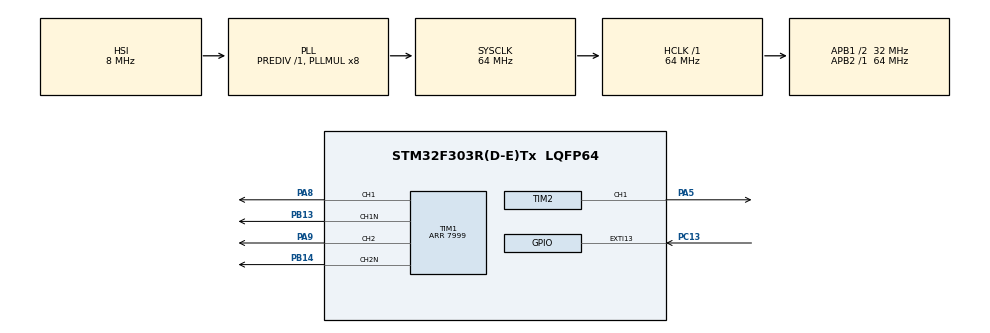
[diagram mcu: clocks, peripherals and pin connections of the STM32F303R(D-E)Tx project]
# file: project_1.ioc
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Dma.Request0=TIM1_CH1
Dma.TIM1_CH1.0.Direction=DMA_MEMORY_TO_PERIPH
Dma.TIM1_CH1.0.Instance=DMA1_Channel2
Dma.TIM1_CH1.0.MemDataAlignment=DMA_MDATAALIGN_HALFWORD
Dma.TIM1_CH1.0.MemInc=DMA_MINC_DISABLE
Dma.TIM1_CH1.0.Mode=DMA_CIRCULAR
Dma.TIM1_CH1.0.PeriphDataAlignment=DMA_PDATAALIGN_HALFWORD
Dma.TIM1_CH1.0.PeriphInc=DMA_PINC_DISABLE
Dma.TIM1_CH1.0.Priority=DMA_PRIORITY_VERY_HIGH
Mcu.Family=STM32F3
Mcu.Name=STM32F303R(D-E)Tx
Mcu.Package=LQFP64
NVIC.DMA1_Channel2_IRQn=true\:0\:0\:false\:false\:true\:false\:true
NVIC.EXTI15_10_IRQn=true\:5\:0\:true\:false\:true\:true\:true
NVIC.PriorityGroup=NVIC_PRIORITYGROUP_4
NVIC.TIM1_UP_TIM16_IRQn=true\:4\:0\:true\:false\:true\:true\:true
NVIC.TIM3_IRQn=true\:6\:0\:true\:false\:true\:true\:true
PA13.Mode=Serial_Wire
PA13.Signal=SYS_JTMS-SWDIO
PA14.Mode=Serial_Wire
PA14.Signal=SYS_JTCK-SWCLK
PA5.Signal=S_TIM2_CH1_ETR
PA8.Signal=S_TIM1_CH1
PA9.Signal=S_TIM1_CH2
PB13.Mode=PWM Generation1 CH1 CH1N
PB13.Signal=TIM1_CH1N
PB14.Mode=PWM Generation2 CH2 CH2N
PB14.Signal=TIM1_CH2N
PC13.Signal=GPXTI13
ProjectManager.HeapSize=0x200
ProjectManager.StackSize=0x400
ProjectManager.TargetToolchain=STM32CubeIDE
RCC.AHBFreq_Value=64000000
RCC.APB1CLKDivider=RCC_HCLK_DIV2
RCC.APB1Freq_Value=32000000
RCC.APB1TimFreq_Value=64000000
RCC.APB2Freq_Value=64000000
RCC.APB2TimFreq_Value=64000000
RCC.CortexFreq_Value=64000000
RCC.HCLKFreq_Value=64000000
RCC.HSE_VALUE=8000000
RCC.HSI_VALUE=8000000
RCC.LSE_VALUE=32768
RCC.PLLMUL=RCC_PLL_MUL8
RCC.SYSCLKFreq_VALUE=64000000
RCC.SYSCLKSourceVirtual=RCC_SYSCLKSOURCE_PLLCLK
RCC.USBFreq_Value=64000000
SH.S_TIM1_CH1.0=TIM1_CH1,PWM Generation1 CH1 CH1N
SH.S_TIM1_CH2.0=TIM1_CH2,PWM Generation2 CH2 CH2N
SH.S_TIM2_CH1_ETR.0=TIM2_CH1,PWM Generation1 CH1
TIM1.Channel-PWM\ Generation1\ CH1\ CH1N=TIM_CHANNEL_1
TIM1.Channel-PWM\ Generation2\ CH2\ CH2N=TIM_CHANNEL_2
TIM1.CounterMode=TIM_COUNTERMODE_CENTERALIGNED1
TIM1.DeadTime=77
TIM1.Period=7999
TIM1.Pulse-PWM\ Generation1\ CH1\ CH1N=0
TIM1.Pulse-PWM\ Generation2\ CH2\ CH2N=0
TIM2.Channel-PWM\ Generation1\ CH1=TIM_CHANNEL_1
TIM2.Period=249
TIM2.Prescaler=63999
TIM2.Pulse-PWM\ Generation1\ CH1=124
TIM3.Period=249
TIM3.Prescaler=63999
VP_TIM1_VS_ClockSourceINT.Mode=Internal
VP_TIM2_VS_ClockSourceINT.Mode=Internal
VP_TIM3_VS_ClockSourceINT.Mode=Internal
VP_TIM3_VS_OPM.Mode=OPM_bit
board=custom

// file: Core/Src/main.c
/* USER CODE BEGIN Header */
/**
  ******************************************************************************
  * @file           : main.c
  * @brief          : Main program body
  ******************************************************************************
  * @attention
  *
  * <h2><center>&copy; Copyright (c) 2021 STMicroelectronics.
  * All rights reserved.</center></h2>
  *
  * This software component is licensed by ST under BSD 3-Clause license,
  * the "License"; You may not use this file except in compliance with the
  * License. You may obtain a copy of the License at:
  *                        opensource.org/licenses/BSD-3-Clause
  *
  ******************************************************************************
  */
/* USER CODE END Header */

#include "main.h"

/* USER CODE BEGIN Includes */
#include "prj.h"
/* USER CODE END Includes */

TIM_HandleTypeDef htim2;
TIM_HandleTypeDef htim3;

void SystemClock_Config(void);
static void MX_GPIO_Init(void);
static void MX_DMA_Init(void);
static void MX_TIM1_Init(void);
static void MX_TIM3_Init(void);
static void MX_TIM2_Init(void);

/* USER CODE BEGIN 0 */
extern int16_t ccr1;
/* USER CODE END 0 */

int main(void)
{

  /* MCU Configuration--------------------------------------------------------*/

  /* Reset of all peripherals, Initializes the Flash interface and the Systick. */
  HAL_Init();

  /* USER CODE BEGIN Init */
  machine_state	= STATE_CNT;

  /* USER CODE END Init */

  /* Configure the system clock */
  SystemClock_Config();

  /* Initialize all configured peripherals */
  MX_GPIO_Init();
  MX_DMA_Init();
  MX_TIM1_Init();
  MX_TIM3_Init();
  MX_TIM2_Init();
  /* USER CODE BEGIN 2 */
  LL_TIM_ClearFlag_UPDATE(TIM3);
  LL_TIM_EnableIT_UPDATE(TIM3);

  LL_TIM_EnableDMAReq_CC1(TIM1);
  LL_DMA_SetPeriphAddress(DMA1, LL_DMA_CHANNEL_2, (uint32_t)&TIM1->CCR1);
  LL_DMA_SetMemoryAddress(DMA1, LL_DMA_CHANNEL_2, (uint32_t)&ccr1);
  LL_DMA_SetDataLength(DMA1, LL_DMA_CHANNEL_2, 1);
  LL_DMA_EnableChannel(DMA1, LL_DMA_CHANNEL_2);
  /* USER CODE END 2 */

  /* Infinite loop */
  /* USER CODE BEGIN WHILE */
  while (1)
  {
    state_machine_executor();
    /* USER CODE END WHILE */

  }
}

void SystemClock_Config(void)
{
  RCC_OscInitTypeDef RCC_OscInitStruct = {0};
  RCC_ClkInitTypeDef RCC_ClkInitStruct = {0};
  RCC_PeriphCLKInitTypeDef PeriphClkInit = {0};

  /** Initializes the CPU, AHB and APB busses clocks
  */
  RCC_OscInitStruct.OscillatorType = RCC_OSCILLATORTYPE_HSI;
  RCC_OscInitStruct.HSIState = RCC_HSI_ON;
  RCC_OscInitStruct.HSICalibrationValue = RCC_HSICALIBRATION_DEFAULT;
  RCC_OscInitStruct.PLL.PLLState = RCC_PLL_ON;
  RCC_OscInitStruct.PLL.PLLSource = RCC_PLLSOURCE_HSI;
  RCC_OscInitStruct.PLL.PLLMUL = RCC_PLL_MUL8;
  RCC_OscInitStruct.PLL.PREDIV = RCC_PREDIV_DIV1;
  if (HAL_RCC_OscConfig(&RCC_OscInitStruct) != HAL_OK)
  {
    Error_Handler();
  }
  /** Initializes the CPU, AHB and APB busses clocks
  */
  RCC_ClkInitStruct.ClockType = RCC_CLOCKTYPE_HCLK|RCC_CLOCKTYPE_SYSCLK
                              |RCC_CLOCKTYPE_PCLK1|RCC_CLOCKTYPE_PCLK2;
  RCC_ClkInitStruct.SYSCLKSource = RCC_SYSCLKSOURCE_PLLCLK;
  RCC_ClkInitStruct.AHBCLKDivider = RCC_SYSCLK_DIV1;
  RCC_ClkInitStruct.APB1CLKDivider = RCC_HCLK_DIV2;
  RCC_ClkInitStruct.APB2CLKDivider = RCC_HCLK_DIV1;

  if (HAL_RCC_ClockConfig(&RCC_ClkInitStruct, FLASH_LATENCY_2) != HAL_OK)
  {
    Error_Handler();
  }
  PeriphClkInit.PeriphClockSelection = RCC_PERIPHCLK_TIM1|RCC_PERIPHCLK_TIM2
                              |RCC_PERIPHCLK_TIM34;
  PeriphClkInit.Tim1ClockSelection = RCC_TIM1CLK_HCLK;
  PeriphClkInit.Tim2ClockSelection = RCC_TIM2CLK_HCLK;
  PeriphClkInit.Tim34ClockSelection = RCC_TIM34CLK_HCLK;
  if (HAL_RCCEx_PeriphCLKConfig(&PeriphClkInit) != HAL_OK)
  {
    Error_Handler();
  }
}

static void MX_TIM1_Init(void)
{

  LL_TIM_InitTypeDef TIM_InitStruct = {0};
  LL_TIM_OC_InitTypeDef TIM_OC_InitStruct = {0};
  LL_TIM_BDTR_InitTypeDef TIM_BDTRInitStruct = {0};

  LL_GPIO_InitTypeDef GPIO_InitStruct = {0};

  /* Peripheral clock enable */
  LL_APB2_GRP1_EnableClock(LL_APB2_GRP1_PERIPH_TIM1);

  /* TIM1 DMA Init */

  /* TIM1_CH1 Init */
  LL_DMA_SetDataTransferDirection(DMA1, LL_DMA_CHANNEL_2, LL_DMA_DIRECTION_MEMORY_TO_PERIPH);

  LL_DMA_SetChannelPriorityLevel(DMA1, LL_DMA_CHANNEL_2, LL_DMA_PRIORITY_VERYHIGH);

  LL_DMA_SetMode(DMA1, LL_DMA_CHANNEL_2, LL_DMA_MODE_CIRCULAR);

  LL_DMA_SetPeriphIncMode(DMA1, LL_DMA_CHANNEL_2, LL_DMA_PERIPH_NOINCREMENT);

  LL_DMA_SetMemoryIncMode(DMA1, LL_DMA_CHANNEL_2, LL_DMA_MEMORY_NOINCREMENT);

  LL_DMA_SetPeriphSize(DMA1, LL_DMA_CHANNEL_2, LL_DMA_PDATAALIGN_HALFWORD);

  LL_DMA_SetMemorySize(DMA1, LL_DMA_CHANNEL_2, LL_DMA_MDATAALIGN_HALFWORD);

  /* TIM1 interrupt Init */
  NVIC_SetPriority(TIM1_UP_TIM16_IRQn, NVIC_EncodePriority(NVIC_GetPriorityGrouping(),4, 0));
  NVIC_EnableIRQ(TIM1_UP_TIM16_IRQn);

  TIM_InitStruct.Prescaler = 0;
  TIM_InitStruct.CounterMode = LL_TIM_COUNTERMODE_CENTER_UP;
  TIM_InitStruct.Autoreload = 7999;
  TIM_InitStruct.ClockDivision = LL_TIM_CLOCKDIVISION_DIV1;
  TIM_InitStruct.RepetitionCounter = 0;
  LL_TIM_Init(TIM1, &TIM_InitStruct);
  LL_TIM_DisableARRPreload(TIM1);
  LL_TIM_SetClockSource(TIM1, LL_TIM_CLOCKSOURCE_INTERNAL);
  LL_TIM_OC_EnablePreload(TIM1, LL_TIM_CHANNEL_CH1);
  TIM_OC_InitStruct.OCMode = LL_TIM_OCMODE_PWM1;
  TIM_OC_InitStruct.OCState = LL_TIM_OCSTATE_DISABLE;
  TIM_OC_InitStruct.OCNState = LL_TIM_OCSTATE_DISABLE;
  TIM_OC_InitStruct.CompareValue = 0;
  TIM_OC_InitStruct.OCPolarity = LL_TIM_OCPOLARITY_HIGH;
  TIM_OC_InitStruct.OCNPolarity = LL_TIM_OCPOLARITY_HIGH;
  TIM_OC_InitStruct.OCIdleState = LL_TIM_OCIDLESTATE_LOW;
  TIM_OC_InitStruct.OCNIdleState = LL_TIM_OCIDLESTATE_LOW;
  LL_TIM_OC_Init(TIM1, LL_TIM_CHANNEL_CH1, &TIM_OC_InitStruct);
  LL_TIM_OC_DisableFast(TIM1, LL_TIM_CHANNEL_CH1);
  LL_TIM_OC_EnablePreload(TIM1, LL_TIM_CHANNEL_CH2);
  TIM_OC_InitStruct.OCState = LL_TIM_OCSTATE_DISABLE;
  TIM_OC_InitStruct.OCNState = LL_TIM_OCSTATE_DISABLE;
  LL_TIM_OC_Init(TIM1, LL_TIM_CHANNEL_CH2, &TIM_OC_InitStruct);
  LL_TIM_OC_DisableFast(TIM1, LL_TIM_CHANNEL_CH2);
  LL_TIM_SetTriggerOutput(TIM1, LL_TIM_TRGO_RESET);
  LL_TIM_SetTriggerOutput2(TIM1, LL_TIM_TRGO2_RESET);
  LL_TIM_DisableMasterSlaveMode(TIM1);
  TIM_BDTRInitStruct.OSSRState = LL_TIM_OSSR_DISABLE;
  TIM_BDTRInitStruct.OSSIState = LL_TIM_OSSI_DISABLE;
  TIM_BDTRInitStruct.LockLevel = LL_TIM_LOCKLEVEL_OFF;
  TIM_BDTRInitStruct.DeadTime = 77;
  TIM_BDTRInitStruct.BreakState = LL_TIM_BREAK_DISABLE;
  TIM_BDTRInitStruct.BreakPolarity = LL_TIM_BREAK_POLARITY_HIGH;
  TIM_BDTRInitStruct.BreakFilter = LL_TIM_BREAK_FILTER_FDIV1;
  TIM_BDTRInitStruct.Break2State = LL_TIM_BREAK2_DISABLE;
  TIM_BDTRInitStruct.Break2Polarity = LL_TIM_BREAK2_POLARITY_HIGH;
  TIM_BDTRInitStruct.Break2Filter = LL_TIM_BREAK2_FILTER_FDIV1;
  TIM_BDTRInitStruct.AutomaticOutput = LL_TIM_AUTOMATICOUTPUT_DISABLE;
  LL_TIM_BDTR_Init(TIM1, &TIM_BDTRInitStruct);
  LL_AHB1_GRP1_EnableClock(LL_AHB1_GRP1_PERIPH_GPIOB);
  LL_AHB1_GRP1_EnableClock(LL_AHB1_GRP1_PERIPH_GPIOA);
  /**TIM1 GPIO Configuration
  PB13   ------> TIM1_CH1N
  PB14   ------> TIM1_CH2N
  PA8   ------> TIM1_CH1
  PA9   ------> TIM1_CH2
  */
  GPIO_InitStruct.Pin = LL_GPIO_PIN_13|LL_GPIO_PIN_14;
  GPIO_InitStruct.Mode = LL_GPIO_MODE_ALTERNATE;
  GPIO_InitStruct.Speed = LL_GPIO_SPEED_FREQ_LOW;
  GPIO_InitStruct.OutputType = LL_GPIO_OUTPUT_PUSHPULL;
  GPIO_InitStruct.Pull = LL_GPIO_PULL_NO;
  GPIO_InitStruct.Alternate = LL_GPIO_AF_6;
  LL_GPIO_Init(GPIOB, &GPIO_InitStruct);

  GPIO_InitStruct.Pin = LL_GPIO_PIN_8|LL_GPIO_PIN_9;
  GPIO_InitStruct.Mode = LL_GPIO_MODE_ALTERNATE;
  GPIO_InitStruct.Speed = LL_GPIO_SPEED_FREQ_LOW;
  GPIO_InitStruct.OutputType = LL_GPIO_OUTPUT_PUSHPULL;
  GPIO_InitStruct.Pull = LL_GPIO_PULL_NO;
  GPIO_InitStruct.Alternate = LL_GPIO_AF_6;
  LL_GPIO_Init(GPIOA, &GPIO_InitStruct);

}

static void MX_TIM2_Init(void)
{

  TIM_ClockConfigTypeDef sClockSourceConfig = {0};
  TIM_MasterConfigTypeDef sMasterConfig = {0};
  TIM_OC_InitTypeDef sConfigOC = {0};

  htim2.Instance = TIM2;
  htim2.Init.Prescaler = 63999;
  htim2.Init.CounterMode = TIM_COUNTERMODE_UP;
  htim2.Init.Period = 249;
  htim2.Init.ClockDivision = TIM_CLOCKDIVISION_DIV1;
  htim2.Init.AutoReloadPreload = TIM_AUTORELOAD_PRELOAD_DISABLE;
  if (HAL_TIM_Base_Init(&htim2) != HAL_OK)
  {
    Error_Handler();
  }
  sClockSourceConfig.ClockSource = TIM_CLOCKSOURCE_INTERNAL;
  if (HAL_TIM_ConfigClockSource(&htim2, &sClockSourceConfig) != HAL_OK)
  {
    Error_Handler();
  }
  if (HAL_TIM_PWM_Init(&htim2) != HAL_OK)
  {
    Error_Handler();
  }
  sMasterConfig.MasterOutputTrigger = TIM_TRGO_RESET;
  sMasterConfig.MasterSlaveMode = TIM_MASTERSLAVEMODE_DISABLE;
  if (HAL_TIMEx_MasterConfigSynchronization(&htim2, &sMasterConfig) != HAL_OK)
  {
    Error_Handler();
  }
  sConfigOC.OCMode = TIM_OCMODE_PWM1;
  sConfigOC.Pulse = 124;
  sConfigOC.OCPolarity = TIM_OCPOLARITY_HIGH;
  sConfigOC.OCFastMode = TIM_OCFAST_DISABLE;
  if (HAL_TIM_PWM_ConfigChannel(&htim2, &sConfigOC, TIM_CHANNEL_1) != HAL_OK)
  {
    Error_Handler();
  }
  HAL_TIM_MspPostInit(&htim2);

}

static void MX_TIM3_Init(void)
{

  TIM_ClockConfigTypeDef sClockSourceConfig = {0};
  TIM_MasterConfigTypeDef sMasterConfig = {0};

  htim3.Instance = TIM3;
  htim3.Init.Prescaler = 63999;
  htim3.Init.CounterMode = TIM_COUNTERMODE_UP;
  htim3.Init.Period = 249;
  htim3.Init.ClockDivision = TIM_CLOCKDIVISION_DIV1;
  htim3.Init.AutoReloadPreload = TIM_AUTORELOAD_PRELOAD_DISABLE;
  if (HAL_TIM_Base_Init(&htim3) != HAL_OK)
  {
    Error_Handler();
  }
  sClockSourceConfig.ClockSource = TIM_CLOCKSOURCE_INTERNAL;
  if (HAL_TIM_ConfigClockSource(&htim3, &sClockSourceConfig) != HAL_OK)
  {
    Error_Handler();
  }
  if (HAL_TIM_OnePulse_Init(&htim3, TIM_OPMODE_SINGLE) != HAL_OK)
  {
    Error_Handler();
  }
  sMasterConfig.MasterOutputTrigger = TIM_TRGO_RESET;
  sMasterConfig.MasterSlaveMode = TIM_MASTERSLAVEMODE_DISABLE;
  if (HAL_TIMEx_MasterConfigSynchronization(&htim3, &sMasterConfig) != HAL_OK)
  {
    Error_Handler();
  }

}

static void MX_DMA_Init(void)
{

  /* DMA controller clock enable */
  __HAL_RCC_DMA1_CLK_ENABLE();

  /* DMA interrupt init */
  /* DMA1_Channel2_IRQn interrupt configuration */
  NVIC_SetPriority(DMA1_Channel2_IRQn, NVIC_EncodePriority(NVIC_GetPriorityGrouping(),0, 0));
  NVIC_EnableIRQ(DMA1_Channel2_IRQn);

}

static void MX_GPIO_Init(void)
{
  GPIO_InitTypeDef GPIO_InitStruct = {0};

  /* GPIO Ports Clock Enable */
  __HAL_RCC_GPIOC_CLK_ENABLE();
  __HAL_RCC_GPIOA_CLK_ENABLE();
  __HAL_RCC_GPIOB_CLK_ENABLE();

  /*Configure GPIO pin : PC13 */
  GPIO_InitStruct.Pin = GPIO_PIN_13;
  GPIO_InitStruct.Mode = GPIO_MODE_IT_RISING;
  GPIO_InitStruct.Pull = GPIO_NOPULL;
  HAL_GPIO_Init(GPIOC, &GPIO_InitStruct);

  /* EXTI interrupt init*/
  HAL_NVIC_SetPriority(EXTI15_10_IRQn, 5, 0);
  HAL_NVIC_EnableIRQ(EXTI15_10_IRQn);

}

void Error_Handler(void)
{
}

/************************ (C) COPYRIGHT STMicroelectronics *****END OF FILE****/
